# HC32F558 register map
File version: 1.0
CPU: CM4 r0p1, little endian, MPU, FPU, 4 interrupt priority bits
Registers are 32-bit, read-write, reset 0x0 unless marked. A register's access mark holds for its fields unless they carry their own. Offsets are from the block's base; [hi:lo] are bit positions; {n}, {i} and the like mark numbered series; 'fields as' and 'values as' point back to an identical list.

## TMR61 — desc TMR6
Base 0x40018000
Same registers: TMR62 0x40018400, TMR63 0x40018800, TMR64 0x40018C00, TMR65 0x40019000, TMR66 0x40019400
0x00 CNTER
0x04 UPDAR
0x40 PERAR reset 0xFFFFFFFF
0x44 PERBR reset 0xFFFFFFFF
0x48 PERCR reset 0xFFFFFFFF
0x80 GCMAR reset 0xFFFFFFFF
0x84 GCMBR reset 0xFFFFFFFF
0x88 GCMCR reset 0xFFFFFFFF
0x8C GCMDR reset 0xFFFFFFFF
0x90 GCMER reset 0xFFFFFFFF
0x94 GCMFR reset 0xFFFFFFFF
0xC0 SCMAR reset 0xFFFFFFFF
0xC4 SCMBR reset 0xFFFFFFFF
0xC8 SCMCR reset 0xFFFFFFFF
0xCC SCMDR reset 0xFFFFFFFF
0xD0 SCMER reset 0xFFFFFFFF
0xD4 SCMFR reset 0xFFFFFFFF
0x100 DTUAR reset 0xFFFFFFFF
0x104 DTDAR reset 0xFFFFFFFF
0x108 DTUBR reset 0xFFFFFFFF
0x10C DTDBR reset 0xFFFFFFFF
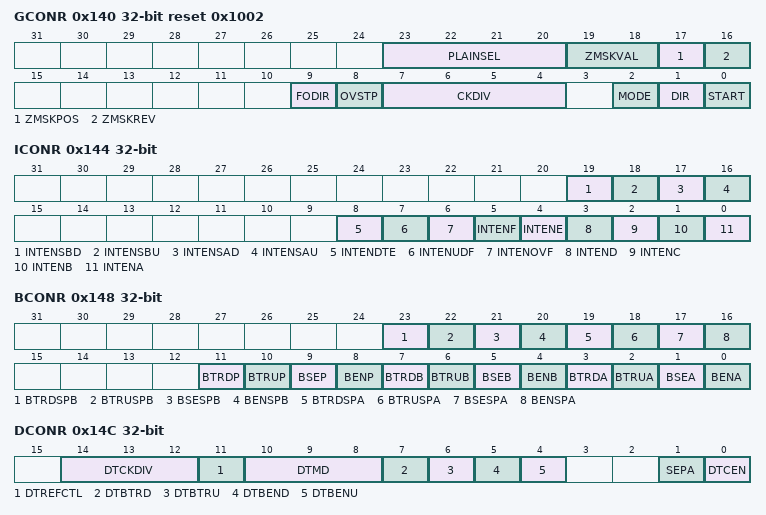
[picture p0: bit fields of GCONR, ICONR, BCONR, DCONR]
0x140 GCONR reset 0x1002
  [23:20] PLAINSEL, [19:18] ZMSKVAL, [17] ZMSKPOS, [16] ZMSKREV, [9] FODIR, [8] OVSTP, [7:4] CKDIV, [2] MODE, [1] DIR, [0] START
0x144 ICONR
  [19] INTENSBD, [18] INTENSBU, [17] INTENSAD, [16] INTENSAU, [8] INTENDTE, [7] INTENUDF, [6] INTENOVF, [5] INTENF, [4] INTENE, [3] INTEND, [2] INTENC, [1] INTENB, [0] INTENA
0x148 BCONR
  [23] BTRDSPB, [22] BTRUSPB, [21] BSESPB, [20] BENSPB, [19] BTRDSPA, [18] BTRUSPA, [17] BSESPA, [16] BENSPA, [11] BTRDP, [10] BTRUP, [9] BSEP, [8] BENP, [7] BTRDB, [6] BTRUB, [5] BSEB, [4] BENB, [3] BTRDA, [2] BTRUA, [1] BSEA, [0] BENA
0x14C DCONR
  [14:12] DTCKDIV, [11] DTREFCTL, [10:8] DTMD, [7] DTBTRD, [6] DTBTRU, [5] DTBEND, [4] DTBENU, [1] SEPA, [0] DTCEN
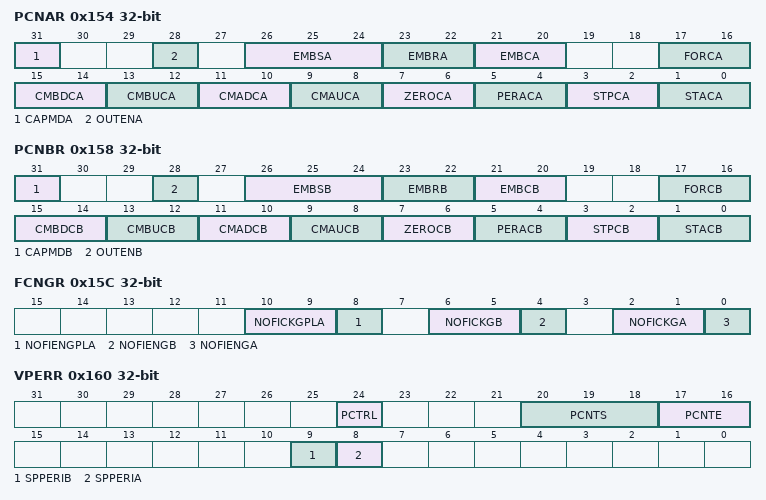
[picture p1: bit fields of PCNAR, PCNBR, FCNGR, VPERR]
0x154 PCNAR
  [31] CAPMDA, [28] OUTENA, [26:24] EMBSA, [23:22] EMBRA, [21:20] EMBCA, [17:16] FORCA, [15:14] CMBDCA, [13:12] CMBUCA, [11:10] CMADCA, [9:8] CMAUCA, [7:6] ZEROCA, [5:4] PERACA, [3:2] STPCA, [1:0] STACA
0x158 PCNBR
  [31] CAPMDB, [28] OUTENB, [26:24] EMBSB, [23:22] EMBRB, [21:20] EMBCB, [17:16] FORCB, [15:14] CMBDCB, [13:12] CMBUCB, [11:10] CMADCB, [9:8] CMAUCB, [7:6] ZEROCB, [5:4] PERACB, [3:2] STPCB, [1:0] STACB
0x15C FCNGR
  [10:9] NOFICKGPLA, [8] NOFIENGPLA, [6:5] NOFICKGB, [4] NOFIENGB, [2:1] NOFICKGA, [0] NOFIENGA
0x160 VPERR
  [24] PCTRL, [20:18] PCNTS, [17:16] PCNTE, [9] SPPERIB, [8] SPPERIA
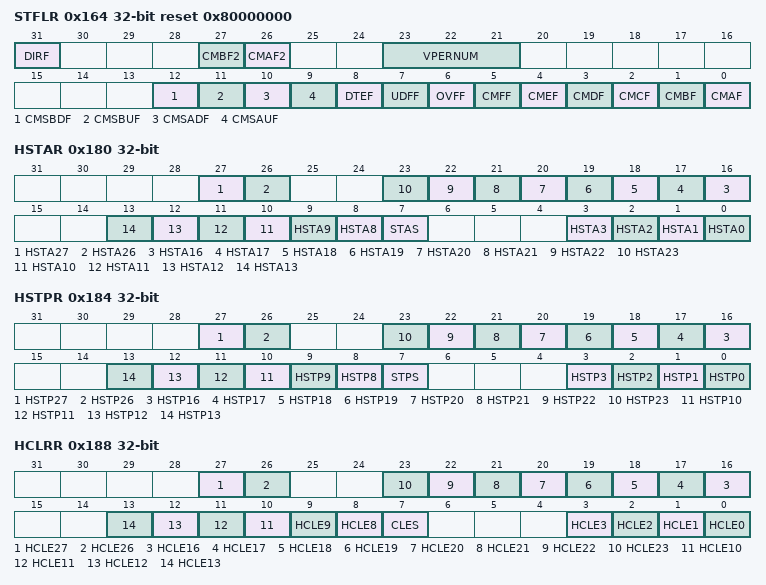
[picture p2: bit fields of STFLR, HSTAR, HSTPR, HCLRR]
0x164 STFLR reset 0x80000000
  [31] DIRF ro, [27] CMBF2, [26] CMAF2, [23:21] VPERNUM ro, [12] CMSBDF, [11] CMSBUF, [10] CMSADF, [9] CMSAUF, [8] DTEF ro, [7] UDFF, [6] OVFF, [5] CMFF, [4] CMEF, [3] CMDF, [2] CMCF, [1] CMBF, [0] CMAF
0x180 HSTAR
  [27] HSTA27, [26] HSTA26, [n] HSTA{n} (n=16..23), [n] HSTA{n} (n=8..13), [7] STAS, [n] HSTA{n} (n=0..3)
0x184 HSTPR
  [27] HSTP27, [26] HSTP26, [n] HSTP{n} (n=16..23), [n] HSTP{n} (n=8..13), [7] STPS, [n] HSTP{n} (n=0..3)
0x188 HCLRR
  [27] HCLE27, [26] HCLE26, [n] HCLE{n} (n=16..23), [n] HCLE{n} (n=8..13), [7] CLES, [n] HCLE{n} (n=0..3)
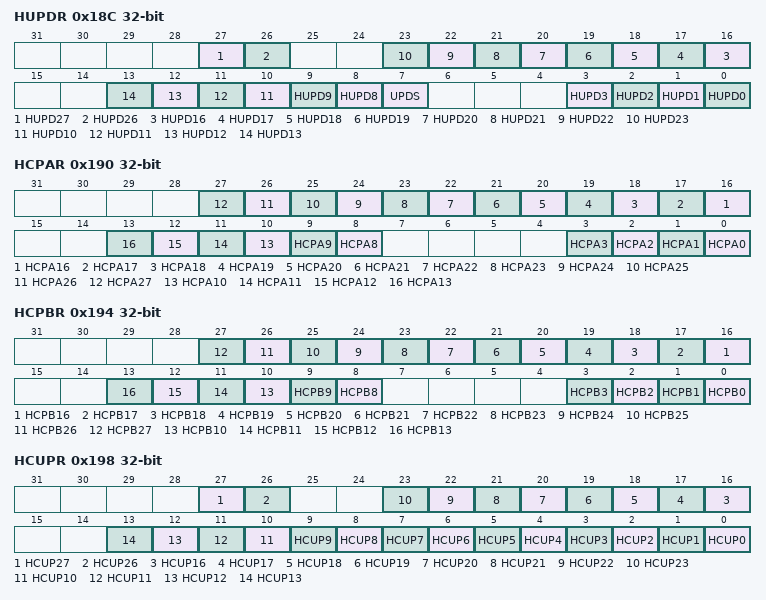
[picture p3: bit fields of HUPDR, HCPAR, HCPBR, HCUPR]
0x18C HUPDR
  [27] HUPD27, [26] HUPD26, [n] HUPD{n} (n=16..23), [n] HUPD{n} (n=8..13), [7] UPDS, [n] HUPD{n} (n=0..3)
0x190 HCPAR
  [n] HCPA{n} (n=16..27), [n] HCPA{n} (n=8..13), [n] HCPA{n} (n=0..3)
0x194 HCPBR
  [n] HCPB{n} (n=16..27), [n] HCPB{n} (n=8..13), [n] HCPB{n} (n=0..3)
0x198 HCUPR
  [27] HCUP27, [26] HCUP26, [n] HCUP{n} (n=16..23), [n] HCUP{n} (n=0..13)
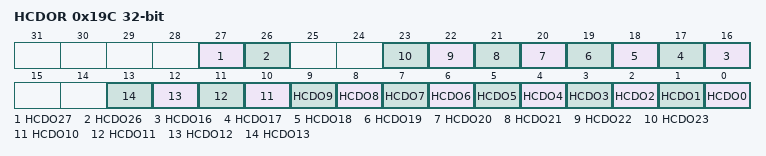
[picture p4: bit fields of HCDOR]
0x19C HCDOR
  [27] HCDO27, [26] HCDO26, [n] HCDO{n} (n=16..23), [n] HCDO{n} (n=0..13)

## TMR6_COMMON
Base 0x40018300
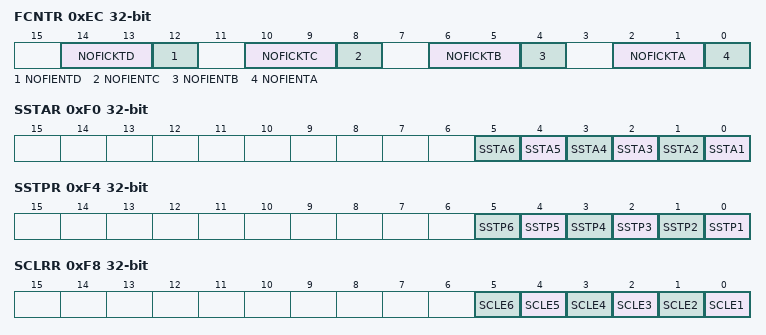
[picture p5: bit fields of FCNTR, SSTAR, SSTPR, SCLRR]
0xEC FCNTR
  [14:13] NOFICKTD, [12] NOFIENTD, [10:9] NOFICKTC, [8] NOFIENTC, [6:5] NOFICKTB, [4] NOFIENTB, [2:1] NOFICKTA, [0] NOFIENTA
0xF0 SSTAR
  [n-1] SSTA{n} (n=1..6)
0xF4 SSTPR
  [n-1] SSTP{n} (n=1..6)
0xF8 SCLRR
  [n-1] SCLE{n} (n=1..6)
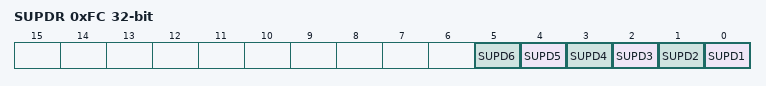
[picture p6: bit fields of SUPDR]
0xFC SUPDR
  [n-1] SUPD{n} (n=1..6)

## TRLPWM1 — desc TRLPWM
Base 0x4003A400
Same registers: TRLPWM2 0x4003AC00
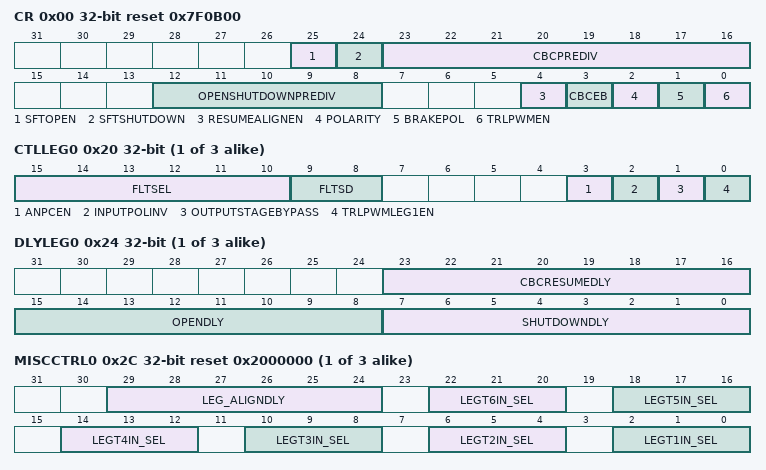
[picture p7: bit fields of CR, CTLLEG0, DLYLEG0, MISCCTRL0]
0x00 CR reset 0x7F0B00
  [25] SFTOPEN, [24] SFTSHUTDOWN, [23:16] CBCPREDIV, [12:8] OPENSHUTDOWNPREDIV, [4] RESUMEALIGNEN, [3] CBCEB, [2] POLARITY, [1] BRAKEPOL, [0] TRLPWMEN
0x04 BRAKESR ro
  [0] BRAKE
0x08 ISR ro
  [0] SHUTDOWNSEQOCCUR
0x0C ICR
  [0] SHUTDOWNSEQOCCURCLR
0x10 IER
  [0] SHUTDOWNSEQOCCURIE
{0x20+0x20*i} CTLLEG{i} (i=0..2)
  [15:10] FLTSEL, [9:8] FLTSD, [3] ANPCEN, [2] INPUTPOLINV, [1] OUTPUTSTAGEBYPASS, [0] TRLPWMLEG1EN
{0x24+0x20*i} DLYLEG{i} (i=0..2)
  [23:16] CBCRESUMEDLY, [15:8] OPENDLY, [7:0] SHUTDOWNDLY
{0x28+0x20*i} SRLEG{i} (i=0..2)
  [1:0] STATUS
{0x2C+0x20*i} MISCCTRL{i} reset 0x2000000 (reset mask 0x3F555000) (i=0..2)
  [29:24] LEG_ALIGNDLY, [4n-2:4n-4] LEGT{n}IN_SEL (n=1..6)
0x3FC REVIDR
  [7:0] REVID

## TRNG
Base 0x40042000
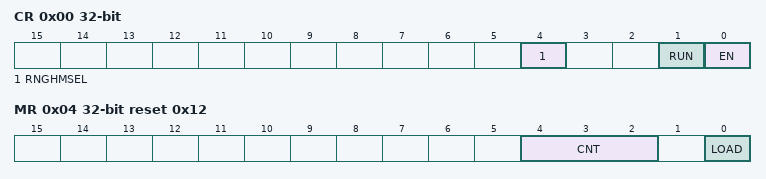
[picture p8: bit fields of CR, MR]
0x00 CR
  [4] RNGHMSEL, [1] RUN, [0] EN
0x04 MR reset 0x12
  [4:2] CNT, [0] LOAD
0x0C DR0 ro reset 0x8000000
0x10 DR1 ro reset 0x8000200

## USART1 — desc USART
Base 0x4001CC00
Same registers: USART2 0x4001D000, USART3 0x4001D400, USART4 0x4001D800
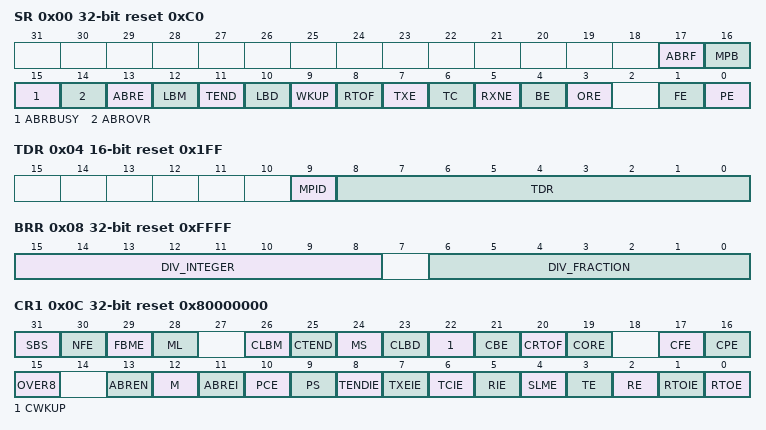
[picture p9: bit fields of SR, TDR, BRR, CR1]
0x00 SR ro reset 0xC0
  [17] ABRF, [16] MPB, [15] ABRBUSY, [14] ABROVR, [13] ABRE, [12] LBM, [11] TEND, [10] LBD, [9] WKUP, [8] RTOF, [7] TXE, [6] TC, [5] RXNE, [4] BE, [3] ORE, [1] FE, [0] PE
0x04 TDR 16-bit reset 0x1FF
  [9] MPID, [8:0] TDR
0x06 RDR 16-bit ro
  [8:0] RDR
0x08 BRR reset 0xFFFF
  [15:8] DIV_INTEGER, [6:0] DIV_FRACTION
0x0C CR1 reset 0x80000000
  [31] SBS, [30] NFE, [29] FBME, [28] ML, [26] CLBM, [25] CTEND, [24] MS, [23] CLBD, [22] CWKUP, [21] CBE, [20] CRTOF, [19] CORE, [17] CFE, [16] CPE, [15] OVER8, [13] ABREN, [12] M, [11] ABREI, [10] PCE, [9] PS, [8] TENDIE, [7] TXEIE, [6] TCIE, [5] RIE, [4] SLME, [3] TE, [2] RE, [1] RTOIE, [0] RTOE
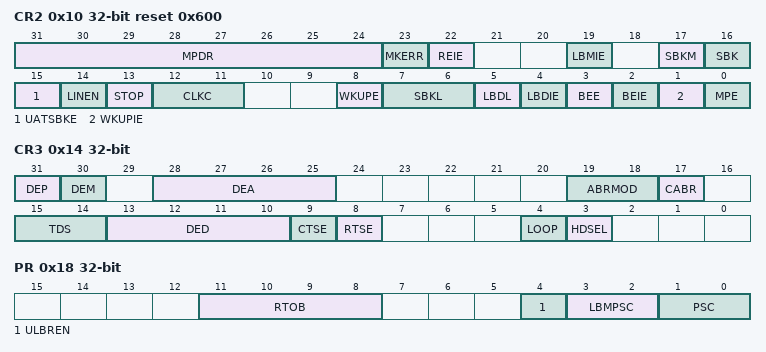
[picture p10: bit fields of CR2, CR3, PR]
0x10 CR2 reset 0x600
  [31:24] MPDR, [23] MKERR, [22] REIE, [19] LBMIE, [17] SBKM, [16] SBK, [15] UATSBKE, [14] LINEN, [13] STOP, [12:11] CLKC, [8] WKUPE, [7:6] SBKL, [5] LBDL, [4] LBDIE, [3] BEE, [2] BEIE, [1] WKUPIE, [0] MPE
0x14 CR3
  [31] DEP, [30] DEM, [28:25] DEA, [19:18] ABRMOD, [17] CABR, [15:14] TDS, [13:10] DED, [9] CTSE, [8] RTSE, [4] LOOP, [3] HDSEL
0x18 PR
  [11:8] RTOB, [4] ULBREN, [3:2] LBMPSC, [1:0] PSC
0x1C LBMC ro
  [15:0] LBMC

## VREF
Base 0x4004F800
0x00 BGRCR
  [0] BGREN
0x04 CSCR
  [0] CSEN
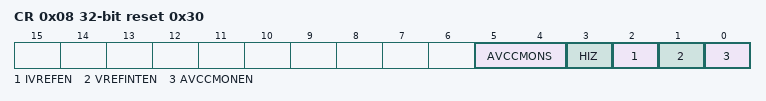
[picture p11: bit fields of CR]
0x08 CR reset 0x30
  [5:4] AVCCMONS, [3] HIZ, [2] IVREFEN, [1] VREFINTEN, [0] AVCCMONEN
0x200 SELV reset 0xC0
  [7:6] VREFVS

## XBAR
Base 0x40021000
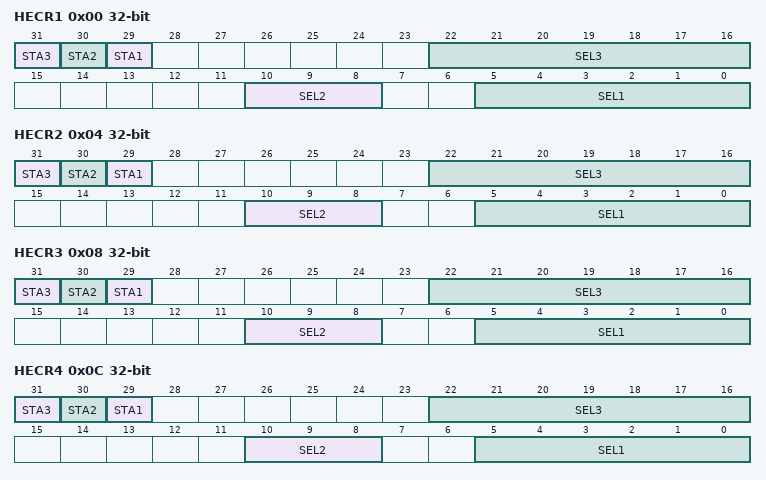
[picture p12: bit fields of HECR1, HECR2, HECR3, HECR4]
0x00 HECR1
  [31] STA3 ro, [30] STA2 ro, [29] STA1 ro, [22:16] SEL3, [10:8] SEL2, [5:0] SEL1
0x04 HECR2
  fields as HECR1
0x08 HECR3
  fields as HECR1
0x0C HECR4
  fields as HECR1
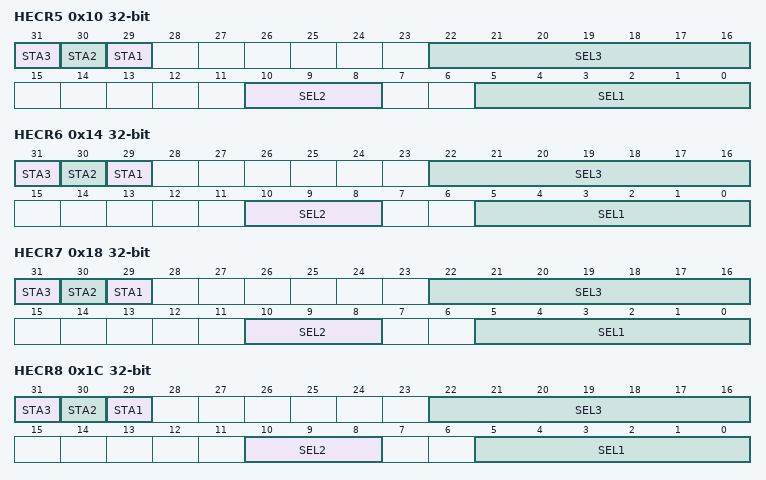
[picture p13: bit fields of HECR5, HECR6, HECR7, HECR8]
0x10 HECR5
  fields as HECR1
0x14 HECR6
  fields as HECR1
0x18 HECR7
  fields as HECR1
0x1C HECR8
  fields as HECR1
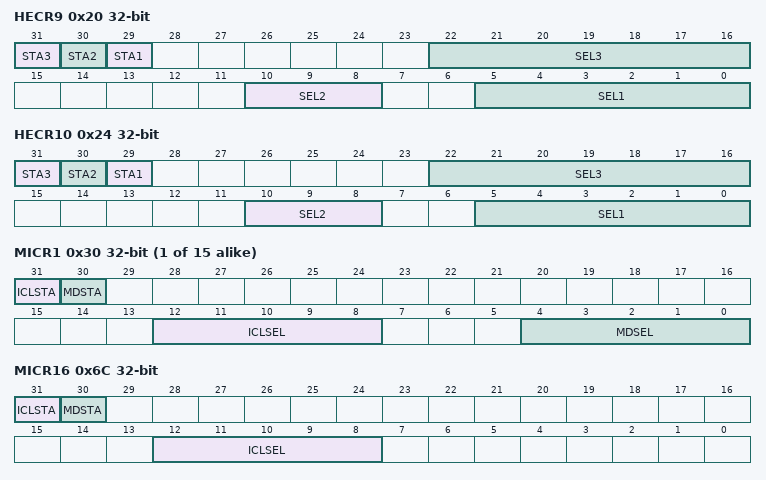
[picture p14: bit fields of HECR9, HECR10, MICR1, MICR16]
0x20 HECR9
  fields as HECR1
0x24 HECR10
  fields as HECR1
{0x2C+4i} MICR{i} (i=1..15)
  [31] ICLSTA ro, [30] MDSTA ro, [12:8] ICLSEL, [4:0] MDSEL
0x6C MICR16
  [31] ICLSTA ro, [30] MDSTA ro, [12:8] ICLSEL
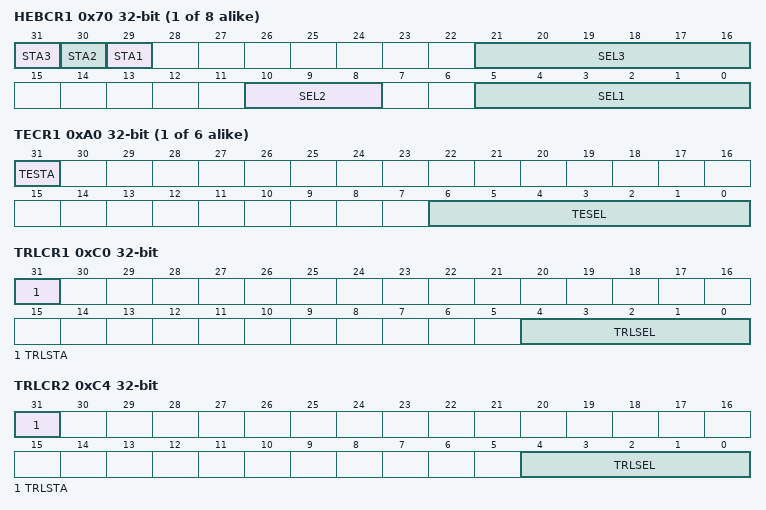
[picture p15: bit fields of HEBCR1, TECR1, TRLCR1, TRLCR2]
{0x6C+4i} HEBCR{i} (i=1..8)
  [31] STA3 ro, [30] STA2 ro, [29] STA1 ro, [21:16] SEL3, [10:8] SEL2, [5:0] SEL1
{0x9C+4i} TECR{i} (i=1..6)
  [31] TESTA ro, [6:0] TESEL
0xC0 TRLCR1
  [31] TRLSTA ro, [4:0] TRLSEL
0xC4 TRLCR2
  [31] TRLSTA ro, [4:0] TRLSEL
